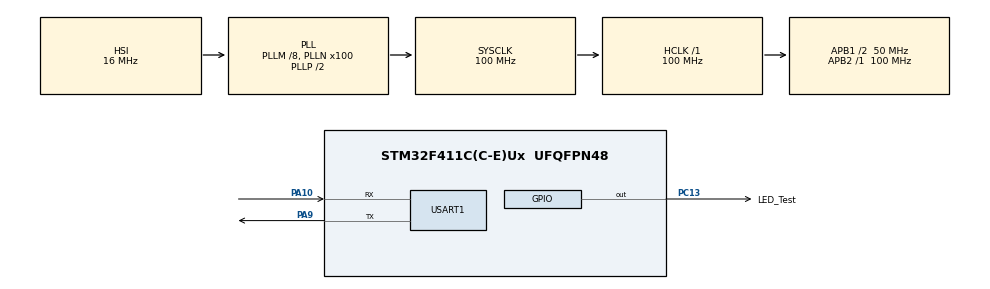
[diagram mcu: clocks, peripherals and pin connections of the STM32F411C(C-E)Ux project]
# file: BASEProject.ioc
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Dma.Request0=USART1_RX
Dma.USART1_RX.0.Direction=DMA_PERIPH_TO_MEMORY
Dma.USART1_RX.0.FIFOMode=DMA_FIFOMODE_DISABLE
Dma.USART1_RX.0.Instance=DMA2_Stream2
Dma.USART1_RX.0.MemDataAlignment=DMA_MDATAALIGN_BYTE
Dma.USART1_RX.0.MemInc=DMA_MINC_ENABLE
Dma.USART1_RX.0.Mode=DMA_CIRCULAR
Dma.USART1_RX.0.PeriphDataAlignment=DMA_PDATAALIGN_BYTE
Dma.USART1_RX.0.PeriphInc=DMA_PINC_DISABLE
Dma.USART1_RX.0.Priority=DMA_PRIORITY_LOW
FREERTOS.Tasks01=defaultTask,24,128,StartDefaultTask,Default,NULL,Dynamic,NULL,NULL
Mcu.Family=STM32F4
Mcu.Name=STM32F411C(C-E)Ux
Mcu.Package=UFQFPN48
NVIC.DMA2_Stream2_IRQn=true\:5\:0\:false\:false\:true\:true\:false\:true\:true
NVIC.PriorityGroup=NVIC_PRIORITYGROUP_4
NVIC.TIM1_UP_TIM10_IRQn=true\:15\:0\:false\:false\:true\:false\:false\:true\:true
NVIC.TimeBase=TIM1_UP_TIM10_IRQn
NVIC.TimeBaseIP=TIM1
NVIC.USART1_IRQn=true\:5\:0\:false\:false\:true\:true\:true\:true\:true
PA10.Mode=Asynchronous
PA10.Signal=USART1_RX
PA13.Mode=Serial_Wire
PA13.Signal=SYS_JTMS-SWDIO
PA14.Mode=Serial_Wire
PA14.Signal=SYS_JTCK-SWCLK
PA9.Mode=Asynchronous
PA9.Signal=USART1_TX
PC13-ANTI_TAMP.GPIO_Label=LED_Test
PC13-ANTI_TAMP.GPIO_ModeDefaultOutputPP=GPIO_MODE_OUTPUT_PP
PC13-ANTI_TAMP.GPIO_PuPd=GPIO_NOPULL
PC13-ANTI_TAMP.GPIO_Speed=GPIO_SPEED_FREQ_LOW
PC13-ANTI_TAMP.PinState=GPIO_PIN_SET
PC13-ANTI_TAMP.Signal=GPIO_Output
PC14-OSC32_IN.Mode=LSE-External-Oscillator
PC14-OSC32_IN.Signal=RCC_OSC32_IN
PC15-OSC32_OUT.Mode=LSE-External-Oscillator
PC15-OSC32_OUT.Signal=RCC_OSC32_OUT
PH0\ -\ OSC_IN.Mode=HSE-External-Oscillator
PH0\ -\ OSC_IN.Signal=RCC_OSC_IN
PH1\ -\ OSC_OUT.Mode=HSE-External-Oscillator
PH1\ -\ OSC_OUT.Signal=RCC_OSC_OUT
ProjectManager.HeapSize=0x200
ProjectManager.StackSize=0x400
ProjectManager.TargetToolchain=MDK-ARM V5.32
RCC.48MHZClocksFreq_Value=50000000
RCC.AHBFreq_Value=100000000
RCC.APB1CLKDivider=RCC_HCLK_DIV2
RCC.APB1Freq_Value=50000000
RCC.APB1TimFreq_Value=100000000
RCC.APB2Freq_Value=100000000
RCC.APB2TimFreq_Value=100000000
RCC.CortexFreq_Value=100000000
RCC.HCLKFreq_Value=100000000
RCC.HSE_VALUE=25000000
RCC.HSI_VALUE=16000000
RCC.PLLM=8
RCC.PLLN=100
RCC.SYSCLKFreq_VALUE=100000000
RCC.SYSCLKSource=RCC_SYSCLKSOURCE_PLLCLK
RCC.VCOOutputFreq_Value=200000000
USART1.VirtualMode=VM_ASYNC
VP_FREERTOS_VS_CMSIS_V2.Mode=CMSIS_V2
VP_SYS_VS_tim1.Mode=TIM1
board=custom

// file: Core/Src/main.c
/* USER CODE BEGIN Header */
/**
  ******************************************************************************
  * @file           : main.c
  * @brief          : Main program body
  ******************************************************************************
  * @attention
  *
  * Copyright (c) 2026 STMicroelectronics.
  * All rights reserved.
  *
  * This software is licensed under terms that can be found in the LICENSE file
  * in the root directory of this software component.
  * If no LICENSE file comes with this software, it is provided AS-IS.
  *
  ******************************************************************************
  */
/* USER CODE END Header */
#include "main.h"
#include "cmsis_os.h"
#include "dma.h"
#include "usart.h"
#include "gpio.h"

/* USER CODE BEGIN Includes */
#include "elog.h"
/* USER CODE END Includes */

void SystemClock_Config(void);
void MX_FREERTOS_Init(void);

int main(void)
{

  /* MCU Configuration--------------------------------------------------------*/

  /* Reset of all peripherals, Initializes the Flash interface and the Systick. */
  HAL_Init();

  /* Configure the system clock */
  SystemClock_Config();

  /* Initialize all configured peripherals */
  MX_GPIO_Init();
  MX_DMA_Init();
  MX_USART1_UART_Init();
  /* USER CODE BEGIN 2 */

 	elog_init();
	/* set EasyLogger log format */
	elog_set_fmt(ELOG_LVL_ASSERT, ELOG_FMT_ALL);
	elog_set_fmt(ELOG_LVL_ERROR, ELOG_FMT_LVL | ELOG_FMT_TAG | ELOG_FMT_TIME);
	elog_set_fmt(ELOG_LVL_WARN, ELOG_FMT_LVL | ELOG_FMT_TAG | ELOG_FMT_TIME);
	elog_set_fmt(ELOG_LVL_INFO, ELOG_FMT_LVL | ELOG_FMT_TAG | ELOG_FMT_TIME);
	elog_set_fmt(ELOG_LVL_DEBUG, ELOG_FMT_ALL & ~(ELOG_FMT_FUNC | ELOG_FMT_T_INFO | ELOG_FMT_P_INFO));
	elog_set_fmt(ELOG_LVL_VERBOSE, ELOG_FMT_ALL & ~(ELOG_FMT_FUNC | ELOG_FMT_T_INFO | ELOG_FMT_P_INFO));
	/* start EasyLogger */
	elog_start();
  /* USER CODE END 2 */

  /* Init scheduler */
  osKernelInitialize();

  /* Call init function for freertos objects (in cmsis_os2.c) */
  MX_FREERTOS_Init();

  /* Start scheduler */
  osKernelStart();

  /* We should never get here as control is now taken by the scheduler */

  /* Infinite loop */
  while (1)
  {

  }
}

void SystemClock_Config(void)
{
  RCC_OscInitTypeDef RCC_OscInitStruct = {0};
  RCC_ClkInitTypeDef RCC_ClkInitStruct = {0};

  /** Configure the main internal regulator output voltage
  */
  __HAL_RCC_PWR_CLK_ENABLE();
  __HAL_PWR_VOLTAGESCALING_CONFIG(PWR_REGULATOR_VOLTAGE_SCALE1);

  /** Initializes the RCC Oscillators according to the specified parameters
  * in the RCC_OscInitTypeDef structure.
  */
  RCC_OscInitStruct.OscillatorType = RCC_OSCILLATORTYPE_HSI;
  RCC_OscInitStruct.HSIState = RCC_HSI_ON;
  RCC_OscInitStruct.HSICalibrationValue = RCC_HSICALIBRATION_DEFAULT;
  RCC_OscInitStruct.PLL.PLLState = RCC_PLL_ON;
  RCC_OscInitStruct.PLL.PLLSource = RCC_PLLSOURCE_HSI;
  RCC_OscInitStruct.PLL.PLLM = 8;
  RCC_OscInitStruct.PLL.PLLN = 100;
  RCC_OscInitStruct.PLL.PLLP = RCC_PLLP_DIV2;
  RCC_OscInitStruct.PLL.PLLQ = 4;
  if (HAL_RCC_OscConfig(&RCC_OscInitStruct) != HAL_OK)
  {
    Error_Handler();
  }

  /** Initializes the CPU, AHB and APB buses clocks
  */
  RCC_ClkInitStruct.ClockType = RCC_CLOCKTYPE_HCLK|RCC_CLOCKTYPE_SYSCLK
                              |RCC_CLOCKTYPE_PCLK1|RCC_CLOCKTYPE_PCLK2;
  RCC_ClkInitStruct.SYSCLKSource = RCC_SYSCLKSOURCE_PLLCLK;
  RCC_ClkInitStruct.AHBCLKDivider = RCC_SYSCLK_DIV1;
  RCC_ClkInitStruct.APB1CLKDivider = RCC_HCLK_DIV2;
  RCC_ClkInitStruct.APB2CLKDivider = RCC_HCLK_DIV1;

  if (HAL_RCC_ClockConfig(&RCC_ClkInitStruct, FLASH_LATENCY_3) != HAL_OK)
  {
    Error_Handler();
  }
}

void HAL_TIM_PeriodElapsedCallback(TIM_HandleTypeDef *htim)
{
  if (htim->Instance == TIM1) {
    HAL_IncTick();
  }
}

void Error_Handler(void)
{
  __disable_irq();
  while (1)
  {
  }
}

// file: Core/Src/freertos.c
/* USER CODE BEGIN Header */
/**
  ******************************************************************************
  * File Name          : freertos.c
  * Description        : Code for freertos applications
  ******************************************************************************
  * @attention
  *
  * Copyright (c) 2026 STMicroelectronics.
  * All rights reserved.
  *
  * This software is licensed under terms that can be found in the LICENSE file
  * in the root directory of this software component.
  * If no LICENSE file comes with this software, it is provided AS-IS.
  *
  ******************************************************************************
  */
/* USER CODE END Header */

#include "FreeRTOS.h"
#include "task.h"
#include "main.h"
#include "cmsis_os.h"

/* USER CODE BEGIN Includes */
#include "uart_task.h"
#include "bsp_uart_driver.h"
#include "mid_circle_buffer.h"

#if 0
#include "usart.h"  //UART_HandleTypeDef huart1;
#include "elog.h"
#include <string.h>  // memset
// #include <stdlib.h>
#include "task.h"   // 任务通知函数  xTaskNotifyFromISR  MAX_DELAY
#include "queue.h" 	//队列
#endif

/* USER CODE END Includes */

/* USER CODE BEGIN Variables */

//#define half_size 2
//#define full_size 2*half_size
//#define half_notify (1<<0)
//#define full_notify (1<<1)

//uint8_t *p_g_buf = NULL;

#if 0
// 环形buffer---�?易版
  uint8_t g_buffer[8]={0};
  uint8_t g_input_buffer[8]={1,2,3,4,5,6,7,8};//输入数据
  uint8_t head=0;
  uint8_t tail=0;
#define buffer_size 8

/**环形buffer 重要三个函数
 * put：将数据写入buffer
 * get：从buffer中读取数�??
 * isEmpty：判断buffer是否为空
 *
 * put：将数据写入buffer--从head�??始写�??
 * get：从buffer中读取数�??--从tail�??始读�??
 */
void buffer_put(uint8_t val){
  // log_a("val %d,head %d",val,head);
    g_buffer[head]=val;//this head g_buffer[head]=val then ++(incremented)
//    if(head==buffer_size){
//        head=0;
//    }
	head=(head+1)%buffer_size;
    // g_buffer[(head++)%buffer_size]=val;

}
uint8_t is_empty(void){
  if(head==tail){ //收尾相等，说明buffer为空
    log_a("buffer full");
    return 1;
  }
  else{return 0;}
}
uint8_t buffer_get(uint8_t *val){
  if(!is_empty()){
    // log_a("buffer_get %d",g_buffer[tail]);
//    *val=g_buffer[tail++];//从tail�??始读取数�??  尾部取出
//    if(tail==buffer_size){
//      tail=0;
//    }
	*val=g_buffer[tail];//从tail�??始读取数�??  尾部取出
    tail=(tail+1)%buffer_size;
	return 1;
  }
  return 0;
}
void my_main(void){
  uint8_t i,val=0;
  for(i=0;i<buffer_size;i++){
    buffer_put(g_input_buffer[i]);
    log_d("i: %d ;head: %d ;val: %d",i,head,g_input_buffer[i]);//this head has been ++(incremented)

    if(i%2==0 && !is_empty()){  //偶数次读取数�??
      buffer_get(&val);
      log_i("tail: %d val: %d",tail,val);
    }
  }
  //打印剩余�?
  while(!is_empty()){
    buffer_get(&val);
    log_i("tail: %d val: %d",tail,val);
  }
}
#endif
void  my_main(void){
  uint8_t g_input_buffer[8]={1,2,3,4,5,6,7,8};//输入数据
  circle_buffer_t * buffer = mid_circle_buffer_create();
  uint8_t val=0;
  if(buffer == NULL){
    log_a("mid_circle_buffer_create failed");
    return;
  }
  for(int i=0;i<CIRCLE_BUFFER_SIZE;i++){
    circle_buf_put(buffer,g_input_buffer[i]);//这里直接传入结构体就�?-内部自动指向arry
    log_d("i: %d ;head: %d ;val: %d",i,buffer->head,buffer->data[i]);
    if(i%2==0 && !circle_buf_is_empty(buffer)){ //偶数次读取数
      circle_buf_get(buffer,&val);
      log_i("tail: %d val: %d",buffer->tail,val);
    }
  }

}
/* USER CODE END Variables */
/* Definitions for defaultTask */
osThreadId_t defaultTaskHandle;
const osThreadAttr_t defaultTask_attributes = {
  .name = "defaultTask",
  .stack_size = 128 * 4,
  .priority = (osPriority_t) osPriorityNormal,
};

/* USER CODE BEGIN FunctionPrototypes */
 /**变换buffer+通知另一个线�? */
osThreadId_t rec_A_TaskHandle;
const osThreadAttr_t rec_A_Task_attributes = {
  .name = "rec_A_Task",
  .stack_size = 128 * 4,
  .priority = (osPriority_t) osPriorityBelowNormal,
};
 /**取出buffer+打印 */
osThreadId_t uart_driver_TaskHandle;
const osThreadAttr_t uart_driver_Task_attributes = {
  .name = "uart_driver_Task",
  .stack_size = 128 * 4,
  .priority = (osPriority_t) osPriorityNormal,//靠近内核，优先级高，先执�?
};
/* USER CODE END FunctionPrototypes */

void StartDefaultTask(void *argument);

void MX_FREERTOS_Init(void); /* (MISRA C 2004 rule 8.1) */

void MX_FREERTOS_Init(void) {

  /* Create the thread(s) */
  /* creation of defaultTask */
  defaultTaskHandle = osThreadNew(StartDefaultTask, NULL, &defaultTask_attributes);

  /* USER CODE BEGIN RTOS_THREADS */
  /**应当有三个线程，
   *
   * */
  ///接收A线程--
  rec_A_TaskHandle = osThreadNew(uart_rec_A_func, NULL, &rec_A_Task_attributes);

 ///bsp_uart_driver---�?中断-中断回调--切换ab-buffer
  uart_driver_TaskHandle = osThreadNew(uart_driver_func, NULL, &uart_driver_Task_attributes);
  // ConvertVoltageTaskHandle = osThreadNew(ConvertVoltageTask, NULL, &ConvertVoltageTask_attributes);

  /* add threads, ... */
  /* USER CODE END RTOS_THREADS */

}

void StartDefaultTask(void *argument)
{
  /* USER CODE BEGIN StartDefaultTask */
//  my_main();
  /* Infinite loop */
	for(;;)
  {
    osDelay(1);
  }
  /* USER CODE END StartDefaultTask */
}

/* USER CODE BEGIN Application */
#if 0
void HAL_UART_TxCpltCallback(UART_HandleTypeDef *huart){
  /**发�?�完成回�? */
  log_i("HAL_UART_TxCpltCallback");
}
// void HAL_UART_halfCpltCallback(UART_HandleTypeDef *huart){
//   /**接收完成回调 */
//   // log_i("HAL_UART_RxCpltCallback");
// }

void HAL_UARTEx_RxEventCallback(UART_HandleTypeDef *huart,uint16_t Size)
{//这里面只是中断写队列
//    struct uart_data *Priv_data;
//    Priv_data=g_cur_uart_dev->priv_data;
// int len = Size;
//    if(huart->Instance == USART1){
//     HAL_UART_Receive_DMA(hhuart, p_g_buf, full_size);//启动dma 接收
//    }
}
xQueueHandle xQueue_A=NULL;
uint32_t send_que_recv_A=0;
void HAL_UART_RxCpltCallback(UART_HandleTypeDef *huart){
  /**接收完成回调 */
  log_i("HAL_UART_RxCpltCallback");
  xQueueSendFromISR(xQueue_A, &send_que_recv_A, NULL);
  log_d("HAL_UART_Receive_IT send notify: %d",send_que_recv_A);

  //持续接收
  HAL_UART_Receive_IT(&huart1, p_g_buf, 1);

}
void ChangeBufTask(void *arg){
  /**切换buffer线程 */
  log_i("ChangeBufTask running---------------");
  uint8_t buff[]="hello world\r\n";
  uint32_t recv_notify=0;
 HAL_UART_Transmit(&huart1,buff,14,100);//HAL_UART_Transmit_DMA_IT

  xQueue_A=xQueueCreate(half_size, sizeof(uint8_t));
  log_i("queue_irq_rec_A Init Success");
  log_i("queue address: %p",xQueue_A);
  /**创建双ABbuffer */
  p_g_buf = (uint8_t *)malloc(sizeof(uint8_t)*full_size);//创建双ABbuffer-返回首地�? 指针
	memset(p_g_buf,0,full_size);

/** HAL_UART_Receive_DMA_IT(&huart1, p_g_buf, full_size);//启动dma 接收
    重新启动DMA接收  --要在if里面不然任何�?个uart触发中断之后都要重新启动 */
    // HAL_UARTEx_ReceiveToIdle_DMA(&huart1, p_g_buf, full_size);

	  if(HAL_OK==HAL_UART_Receive_IT(&huart1, p_g_buf, 1)){  /////uart 只支�?8bit  full_size
//    HAL_UART_Transmit_IT(&huart1, p_g_buf, 1);
		  memset(p_g_buf,0,full_size);
		}
  while(1){
    osDelay(1);

    if(xQueueReceive(xQueue_A, &recv_notify, portMAX_DELAY) == pdTRUE){
      // printf("%c",recv_notify);
      log_d("i will notify OutputTask& changebuffer");
      log_w("recv_notify: %d",recv_notify);
    }
  }
    /***uint8_t i=sizeof(p_g_buf);HAL_UART_Transmit_IT(&huart1, &i, 1);//这个地方只会�?0x04---发的是ascii�?
	  printf("heeeeeello\r\n");
//	HAL_UART_Transmit(&huart1, &i, 1, 100); // 先用阻塞发�?�测�?

// HAL_UART_Transmit_IT(&huart1, p_g_buf, sizeof(p_g_buf));
      //sizeof(p_g_buf)，这只会返回指针的大小（4字节�? */
  /* USER CODE END StartDefaultTask */
}
void OutputTask(void *arg){
  /**取出buffer+打印 */
  log_i("OutputTask running---------------");
  while(1){
    osDelay(1);
	  // log_d("---------");
  }
}
#endif

/* USER CODE END Application */
